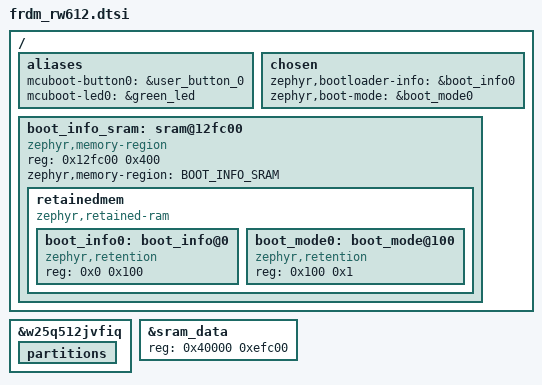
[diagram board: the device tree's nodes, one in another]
/* FRDM-RW612 mcuboot layout.
 *
 * Upstream (frdm_rw612_common.dtsi) partitions the 64 MB w25q512jvfiq as:
 *   boot_partition   @0x000000  128K   (mcuboot)
 *   slot0_partition  @0x020000  3M
 *   slot1_partition  @0x320000  3M
 *   storage_partition@0x620000  58M-128K  (to end of flash)
 *
 * mcuboot and both slots are kept as-is. The single large upstream storage
 * partition is replaced with the fork's standard trio so every app gets the
 * same placement: a small settings partition, raw nvm, and the filesystem
 * filling the rest. storage_partition must exist -- Zephyr's settings
 * subsystem (settings_nvs.c) references it by name.
 *
 * Sector size is 4 KB; all offsets and sizes below are 4 KB aligned and the
 * filesystem ends exactly at the 64 MB flash boundary.
 */
&w25q512jvfiq {
	partitions {
		/delete-node/ partition@620000;
	};
};

/ {
	aliases {
		mcuboot-button0 = &user_button_0;
		mcuboot-led0 = &green_led;
	};
};

#include "frdm_rw612-partitions.dtsi"

/* Bootloader info shared-data area: the last KB of this board's RAM, kept
 * out of the managed RAM so neither image clobbers it. The bootloader
 * writes its boot state here on every boot (BOOT_SHARE_DATA_BOOTINFO ->
 * BLINFO TLVs via boot_write_shared_data()); the application reads the
 * same region to answer the SMP bootloader-info command (RETENTION_
 * BOOTLOADER_INFO_TYPE_MCUBOOT). Carved here because this dtsi applies to
 * both images.
 *
 * A second, one-byte retention cell in the same block backs the boot-mode
 * flag (zephyr,boot-mode): the application sets it to request the
 * bootloader's update mode (reset_to_bootloader() / RunMode.UF2) and the
 * bootloader reads and clears it at boot (io_detect_boot_mode()). SRAM
 * content survives the warm reset that follows the request, which is all a
 * button-less entrance needs; a power cycle simply drops the request.
 */
&sram_data {
	reg = <0x40000 0xefc00>;
};

/ {
	chosen {
		zephyr,bootloader-info = &boot_info0;
		zephyr,boot-mode = &boot_mode0;
	};

	boot_info_sram: sram@12fc00 {
		compatible = "zephyr,memory-region", "mmio-sram";
		reg = <0x12fc00 0x400>;
		zephyr,memory-region = "BOOT_INFO_SRAM";
		status = "okay";

		retainedmem {
			compatible = "zephyr,retained-ram";
			status = "okay";
			#address-cells = <1>;
			#size-cells = <1>;

			boot_info0: boot_info@0 {
				compatible = "zephyr,retention";
				status = "okay";
				reg = <0x0 0x100>;
			};

			boot_mode0: boot_mode@100 {
				compatible = "zephyr,retention";
				status = "okay";
				reg = <0x100 0x1>;
			};
		};
	};
};
